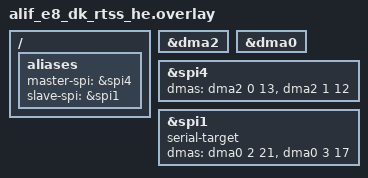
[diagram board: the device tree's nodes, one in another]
/* Copyright (C) 2025 Alif Semiconductor - All Rights Reserved.
 * Use, distribution and modification of this code is permitted under the
 * terms stated in the Alif Semiconductor Software License Agreement
 *
 * You should have received a copy of the Alif Semiconductor Software
 * License Agreement with this file. If not, please write to:
 * contact@alifsemi.com, or visit: https://alifsemi.com/license
 *
 */

/* For SPI master SS(slave select) as:
 * - H/W controlled (default):
 *   - use SS pinmux as H/W
 *     - example for SPI1 as master "PIN_P14_7__SPI1_SS0_C"
 *  "OR"
 * - S/W controlled using gpio:
 *   - use SS pinmux as gpio
 *     - example for SPI1 as master "PIN_P14_7__GPIO"
 *   - define cs-gpios property
 *     - example for SPI1 as master
 *        cs-gpios = <&gpio14 7 GPIO_ACTIVE_LOW>;
 */

/* default SPI master SS(slave select) is H/W controlled,
 * enable this to use as S/W controlled using gpio.
 */
#define SPI_MASTER_SS_SW_CONTROLLED_GPIO   0

/* setting SPI4(LPSPI) as master and SPI1 instance as slave. */
/ {
	aliases {
		master-spi = &spi4;
		slave-spi = &spi1;
	};
};

&dma2 {
	status = "okay";
};

&dma0 {
	status = "okay";
};

&spi4 { /* LPSPI */
	status = "okay";
	dmas = <&dma2 0 13>, <&dma2 1 12>;
/* If user want to use dma0 for master spi(spi4),
 * add below dmas property:
 * dmas = <&dma0 0 25>, <&dma0 1 24>;
 */
	dma-names = "txdma", "rxdma";

#if SPI_MASTER_SS_SW_CONTROLLED_GPIO
	cs-gpios = <&gpio11 7 GPIO_ACTIVE_LOW>;
	/* as we are testing Loopback on the same board,
	 * make sure master interrupt priority is
	 * higher than slave interrupt priority.
	 */
	interrupts = <46 0>;
#endif /* SPI_MASTER_SS_SW_CONTROLLED_GPIO */
};

#if SPI_MASTER_SS_SW_CONTROLLED_GPIO
/* use SPI master SS pinmux as gpio. */
&pinctrl_lpspi{
	group0 {
		pinmux = < PIN_P11_4__LPSPI_MISO_B >,
			 < PIN_P11_5__LPSPI_MOSI_B >,
			 < PIN_P11_6__LPSPI_SCLK_B >,
			 < PIN_P11_7__GPIO >;
		read-enable = < 0x1 >;
	};
};

&gpio11 {
	status = "okay";
};
#endif /* SPI_MASTER_SS_SW_CONTROLLED_GPIO */

&spi1 { /* SPI1 */
	status = "okay";
	serial-target;
	dmas = <&dma0 2 21>, <&dma0 3 17>;
	dma-names = "txdma", "rxdma";

#if SPI_MASTER_SS_SW_CONTROLLED_GPIO
	interrupts = <138 1>;
#endif
};
